# MK20D7 register map
File version: 1.6
Registers are 32-bit, access per field, reset 0x0 unless marked. A register's access mark holds for its fields unless they carry their own. Offsets are from the block's base; [hi:lo] are bit positions.

## UART0 — Serial Communication Interface
Base 0x4006A000; register names take the prefix UART0_
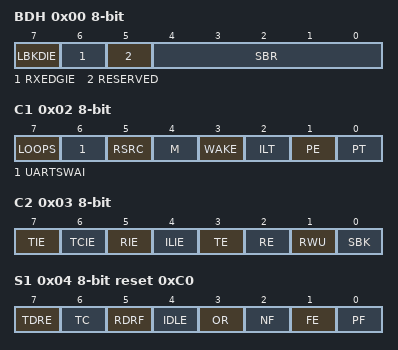
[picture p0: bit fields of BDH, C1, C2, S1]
0x00 BDH 8-bit — UART Baud Rate Registers:High
  [7] LBKDIE rw — LIN Break Detect Interrupt Enable
    0=LBKDIF interrupt requests disabled; 1=LBKDIF interrupt requests enabled
  [6] RXEDGIE rw — RxD Input Active Edge Interrupt Enable
    0=Hardware interrupts from RXEDGIF disabled (use polling); 1=RXEDGIF interrupt request enabled
  [5] RESERVED ro
  [4:0] SBR rw — UART Baud Rate Bits
0x01 BDL 8-bit rw reset 0x4 — UART Baud Rate Registers: Low
  [7:0] SBR — UART Baud Rate Bits
0x02 C1 8-bit rw — UART Control Register 1
  [7] LOOPS — Loop Mode Select
    0=Normal operation; 1=Loop mode where transmitter output is internally connected to receiver input. The receiver input is determined by the RSRC bit.
  [6] UARTSWAI — UART Stops in Wait Mode
    0=UART clock continues to run in wait mode; 1=UART clock freezes while CPU is in wait mode
  [5] RSRC — Receiver Source Select
    0=Selects internal loop back mode and receiver input is internally connected to transmitter output; 1=Single-wire UART mode where the receiver input is connected to the transmit pin input signal
  [4] M — 9-bit or 8-bit Mode Select
    0=Normal - start + 8 data bits (MSB/LSB first as determined by MSBF) + stop; 1=Use - start + 9 data bits (MSB/LSB first as determined by MSBF) + stop
  [3] WAKE — Receiver Wakeup Method Select
    0=Idle-line wakeup; 1=Address-mark wakeup
  [2] ILT — Idle Line Type Select
    0=Idle character bit count starts after start bit; 1=Idle character bit count starts after stop bit
  [1] PE — Parity Enable
    0=Parity function disabled; 1=Parity function enabled
  [0] PT — Parity Type
    0=Even parity; 1=Odd parity
0x03 C2 8-bit rw — UART Control Register 2
  [7] TIE — Transmitter Interrupt or DMA Transfer Enable.
    0=TDRE interrupt and DMA transfer requests disabled; 1=TDRE interrupt or DMA transfer requests enabled
  [6] TCIE — Transmission Complete Interrupt Enable
    0=TC interrupt requests disabled; 1=TC interrupt requests enabled
  [5] RIE — Receiver Full Interrupt or DMA Transfer Enable
    0=RDRF interrupt and DMA transfer requests disabled; 1=RDRF interrupt or DMA transfer requests enabled
  [4] ILIE — Idle Line Interrupt Enable
    0=IDLE interrupt requests disabled; 1=IDLE interrupt requests enabled
  [3] TE — Transmitter Enable
    0=Transmitter off; 1=Transmitter on
  [2] RE — Receiver Enable
    0=Receiver off; 1=Receiver on
  [1] RWU — Receiver Wakeup Control
    0=Normal operation; 1=RWU enables the wakeup function and inhibits further receiver interrupt requests. Normally, hardware wakes the receiver by automatically clearing RWU.
  [0] SBK — Send Break
    0=Normal transmitter operation; 1=Queue break character(s) to be sent
0x04 S1 8-bit ro reset 0xC0 — UART Status Register 1
  [7] TDRE — Transmit Data Register Empty Flag
    0=The amount of data in the transmit buffer is greater than the value indicated by TWFIFO[TXWATER]; 1=The amount of data in the transmit buffer is less than or equal to the value indicated by TWFIFO[TXWATER] at some point in time since the flag has been cleared
  [6] TC — Transmit Complete Flag
    0=Transmitter active (sending data, a preamble, or a break); 1=Transmitter idle (transmission activity complete)
  [5] RDRF — Receive Data Register Full Flag
    0=The number of datawords in the receive buffer is less than the number indicated by RXWATER; 1=The number of datawords in the receive buffer is equal to or greater than the number indicated by RXWATER at some point in time since this flag was last cleared
  [4] IDLE — Idle Line Flag
    0=Receiver input is either active now or has never become active since the IDLE flag was last cleared; 1=Receiver input has become idle or the flag has not been cleared since it last asserted
  [3] OR — Receiver Overrun Flag
    0=No overrun has occurred since the last time the flag was cleared; 1=Overrun has occurred or the overrun flag has not been cleared since the last overrun occured
  [2] NF — Noise Flag
    0=No noise detected since the last time this flag was cleared. If the receive buffer has a depth greater than 1 then there may be data in the receiver buffer that was received with noise.; 1=At least one dataword was received with noise detected since the last time the flag was cleared
  [1] FE — Framing Error Flag
    0=No framing error detected; 1=Framing error
  [0] PF — Parity Error Flag
    0=No parity error has been detected since the last time this flag was cleared. If the receive buffer has a depth greater than 1 then there may be data in the receive buffer what was received with a parity error.; 1=At least one dataword was received with a parity error since the last time this flag was cleared
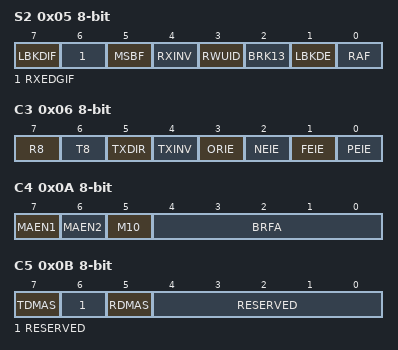
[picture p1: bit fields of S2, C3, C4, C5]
0x05 S2 8-bit — UART Status Register 2
  [7] LBKDIF rw — LIN Break Detect Interrupt Flag
    0=No LIN break character has been detected; 1=LIN break character has been detected
  [6] RXEDGIF rw — RxD Pin Active Edge Interrupt Flag
    0=No active edge on the receive pin has occurred; 1=An active edge on the receive pin has occurred
  [5] MSBF rw — Most Significant Bit First
    0=LSB (bit0) is the first bit that is transmitted following the start bit. Further, the first bit received after the start bit is identified as bit0.; 1=MSB (bit8, bit7 or bit6) is the first bit that is transmitted following the start bit depending on the setting of C1[M] and C1[PE]. Further, the first bit received after the start bit is identified as bit8, bit7 or bit6 depending on the setting of C1[M] and C1[PE].
  [4] RXINV rw — Receive Data Inversion
    0=Receive data is not inverted; 1=Receive data is inverted
  [3] RWUID rw — Receive Wakeup Idle Detect
    0=The S1[IDLE] bit is not set upon detection of an idle character; 1=The S1[IDLE] bit is set upon detection of an idle character
  [2] BRK13 rw — Break Transmit Character Length
    0=Break character is 10, 11, or 12 bits long; 1=Break character is 13 or 14 bits long
  [1] LBKDE rw — LIN Break Detection Enable
    0=Break character is detected at length of 10 bit times (C1[M] = 0), 11 (C1[M] = 1 and C4[M10] = 0), or 12 (C1[M] = 1, C4[M10] = 1, and S1[PE] = 1); 1=Break character is detected at length of 11 bits times (if C1[M] = 0 or 12 bits time (if C1[M] = 1)
  [0] RAF ro — Receiver Active Flag
    0=UART receiver idle/inactive waiting for a start bit; 1=UART receiver active (RxD input not idle)
0x06 C3 8-bit — UART Control Register 3
  [7] R8 ro — Received Bit 8
  [6] T8 rw — Transmit Bit 8
  [5] TXDIR rw — Transmitter Pin Data Direction in Single-Wire mode
    0=TXD pin is an input in single-wire mode; 1=TXD pin is an output in single-wire mode
  [4] TXINV rw — Transmit Data Inversion.
    0=Transmit data is not inverted; 1=Transmit data is inverted
  [3] ORIE rw — Overrun Error Interrupt Enable
    0=OR interrupts are disabled; 1=OR interrupt requests are enabled
  [2] NEIE rw — Noise Error Interrupt Enable
    0=NF interrupt requests are disabled; 1=NF interrupt requests are enabled
  [1] FEIE rw — Framing Error Interrupt Enable
    0=FE interrupt requests are disabled; 1=FE interrupt requests are enabled
  [0] PEIE rw — Parity Error Interrupt Enable
    0=PF interrupt requests are disabled; 1=PF interrupt requests are enabled
0x07 D 8-bit rw — UART Data Register
  [7:0] RT
0x08 MA1 8-bit rw — UART Match Address Registers 1
  [7:0] MA — Match Address
0x09 MA2 8-bit rw — UART Match Address Registers 2
  [7:0] MA — Match Address
0x0A C4 8-bit rw — UART Control Register 4
  [7] MAEN1 — Match Address Mode Enable 1
    0=All data received is transferred to the data buffer if MAEN2 is cleared; 1=All data received with the most significant bit cleared, is discarded. All data received with the most significant bit set, is compared with contents of MA1 register. If no match occurs, the data is discarded. If match occurs, data is transferred to the data buffer.This bit must be cleared when C7816[ISO7816E] is set/enabled.
  [6] MAEN2 — Match Address Mode Enable 2
    0=All data received is transferred to the data buffer if MAEN1 is cleared; 1=All data received with the most significant bit cleared, is discarded. All data received with the most significant bit set, is compared with contents of MA2 register. If no match occurs, the data is discarded. If match occurs, data is transferred to the data buffer.This bit must be cleared when C7816[ISO7816E] is set/enabled.
  [5] M10 — 10-bit Mode select
    0=The parity bit is the ninth bit in the serial transmission; 1=The parity bit is the tenth bit in the serial transmission
  [4:0] BRFA — Baud Rate Fine Adjust
0x0B C5 8-bit — UART Control Register 5
  [7] TDMAS rw — Transmitter DMA Select
    0=If C2[TIE] is set and the S1[TDRE] flag is set, the TDRE interrupt request signal is asserted to request interrupt service; 1=If C2[TIE] is set and the S1[TDRE] flag is set, the TDRE DMA request signal is asserted to request a DMA transfer
  [6] RESERVED ro
  [5] RDMAS rw — Receiver Full DMA Select
    0=If C2[RIE] is set and the S1[RDRF] flag is set, the RDFR interrupt request signal is asserted to request interrupt service; 1=If C2[RIE] is set and the S1[RDRF] flag is set, the RDRF DMA request signal is asserted to request a DMA transfer
  [4:0] RESERVED ro
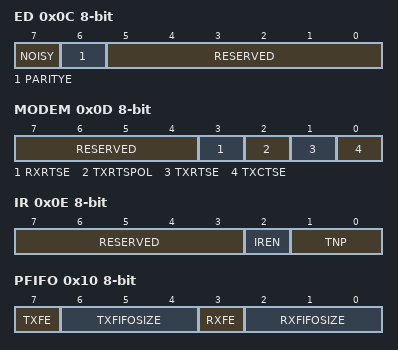
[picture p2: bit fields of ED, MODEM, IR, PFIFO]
0x0C ED 8-bit ro — UART Extended Data Register
  [7] NOISY
    0=The dataword was received without noise; 1=The data was received with noise
  [6] PARITYE
    0=The dataword was received without a parity error; 1=The dataword was received with a parity error
  [5:0] RESERVED
0x0D MODEM 8-bit — UART Modem Register
  [7:4] RESERVED ro
  [3] RXRTSE rw — Receiver request-to-send enable
    0=The receiver has no effect on RTS; 1=RTS is deasserted if the number of characters in the receiver data register (FIFO) is equal to or greater than RWFIFO[RXWATER]. RTS is asserted when the number of characters in the receiver data register (FIFO) is less than RWFIFO[RXWATER].
  [2] TXRTSPOL rw — Transmitter request-to-send polarity
    0=Transmitter RTS is active low; 1=Transmitter RTS is active high
  [1] TXRTSE rw — Transmitter request-to-send enable
    0=The transmitter has no effect on RTS; 1=When a character is placed into an empty transmitter data buffer(FIFO), RTS asserts one bit time before the start bit is transmitted. RTS deasserts one bit time after all characters in the transmitter data buffer(FIFO) and shift register are completely sent, including the last stop bit.
  [0] TXCTSE rw — Transmitter clear-to-send enable
    0=CTS has no effect on the transmitter; 1=Enables clear-to-send operation. The transmitter checks the state of CTS each time it is ready to send a character. If CTS is asserted, the character is sent. If CTS is deasserted, the signal TXD remains in the mark state and transmission is delayed until CTS is asserted. Changes in CTS as a character is being sent do not affect its transmission.
0x0E IR 8-bit — UART Infrared Register
  [7:3] RESERVED ro
  [2] IREN rw — Infrared enable
    0=IR disabled; 1=IR enabled
  [1:0] TNP rw — Transmitter narrow pulse
    0=3/16; 1=1/16; 2=1/32; 3=1/4
0x10 PFIFO 8-bit — UART FIFO Parameters
  [7] TXFE rw — Transmit FIFO Enable
    0=Transmit FIFO is not enabled. Buffer is depth 1. (Legacy support).; 1=Transmit FIFO is enabled. Buffer is depth indicted by TXFIFOSIZE.
  [6:4] TXFIFOSIZE ro — Transmit FIFO. Buffer Depth
    0=Transmit FIFO/Buffer Depth = 1 Dataword; 1=Transmit FIFO/Buffer Depth = 4 Datawords; 2=Transmit FIFO/Buffer Depth = 8 Datawords; 3=Transmit FIFO/Buffer Depth = 16 Datawords; 4=Transmit FIFO/Buffer Depth = 32 Datawords; 5=Transmit FIFO/Buffer Depth = 64 Datawords; 6=Transmit FIFO/Buffer Depth = 128 Datawords
  [3] RXFE rw — Receive FIFO Enable
    0=Receive FIFO is not enabled. Buffer is depth 1. (Legacy support); 1=Receive FIFO is enabled. Buffer is depth indicted by RXFIFOSIZE.
  [2:0] RXFIFOSIZE ro — Receive FIFO. Buffer Depth
    0=Receive FIFO/Buffer Depth = 1 Dataword; 1=Receive FIFO/Buffer Depth = 4 Datawords; 2=Receive FIFO/Buffer Depth = 8 Datawords; 3=Receive FIFO/Buffer Depth = 16 Datawords; 4=Receive FIFO/Buffer Depth = 32 Datawords; 5=Receive FIFO/Buffer Depth = 64 Datawords; 6=Receive FIFO/Buffer Depth = 128 Datawords
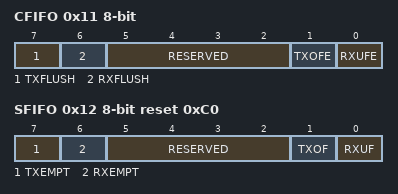
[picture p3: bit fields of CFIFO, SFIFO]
0x11 CFIFO 8-bit — UART FIFO Control Register
  [7] TXFLUSH wo — Transmit FIFO/Buffer Flush
    0=No flush operation occurs; 1=All data in the transmit FIFO/Buffer is cleared out
  [6] RXFLUSH wo — Receive FIFO/Buffer Flush
    0=No flush operation occurs; 1=All data in the receive FIFO/buffer is cleared out
  [5:2] RESERVED ro
  [1] TXOFE rw — Transmit FIFO Overflow Interrupt Enable
    0=TXOF flag does not generate an interrupt to the host; 1=TXOF flag generates an interrupt to the host
  [0] RXUFE rw — Receive FIFO Underflow Interrupt Enable
    0=RXUF flag does not generate an interrupt to the host; 1=RXUF flag generates an interrupt to the host
0x12 SFIFO 8-bit reset 0xC0 — UART FIFO Status Register
  [7] TXEMPT ro — Transmit Buffer/FIFO Empty
    0=Transmit buffer is not empty; 1=Transmit buffer is empty
  [6] RXEMPT ro — Receive Buffer/FIFO Empty
    0=Receive buffer is not empty; 1=Receive buffer is empty
  [5:2] RESERVED ro
  [1] TXOF rw — Transmitter Buffer Overflow Flag
    0=No transmit buffer overflow has occurred since the last time the flag was cleared; 1=At least one transmit buffer overflow has occurred since the last time the flag was cleared
  [0] RXUF rw — Receiver Buffer Underflow Flag
    0=No receive buffer underflow has occurred since the last time the flag was cleared; 1=At least one receive buffer underflow has occurred since the last time the flag was cleared
0x13 TWFIFO 8-bit rw — UART FIFO Transmit Watermark
  [7:0] TXWATER — Transmit Watermark
0x14 TCFIFO 8-bit ro — UART FIFO Transmit Count
  [7:0] TXCOUNT — Transmit Counter
0x15 RWFIFO 8-bit rw reset 0x1 — UART FIFO Receive Watermark
  [7:0] RXWATER — Receive Watermark
0x16 RCFIFO 8-bit ro — UART FIFO Receive Count
  [7:0] RXCOUNT — Receive Counter

## UART1 — Serial Communication Interface
Base 0x4006B000; register names take the prefix UART1_
Registers as UART0.

## UART2 — Serial Communication Interface
Base 0x4006C000; register names take the prefix UART2_
Registers as UART0.

## UART3 — Serial Communication Interface
Base 0x4006D000; register names take the prefix UART3_
Registers as UART0.

## UART4 — Serial Communication Interface
Base 0x400EA000; register names take the prefix UART4_
Registers as UART0.
